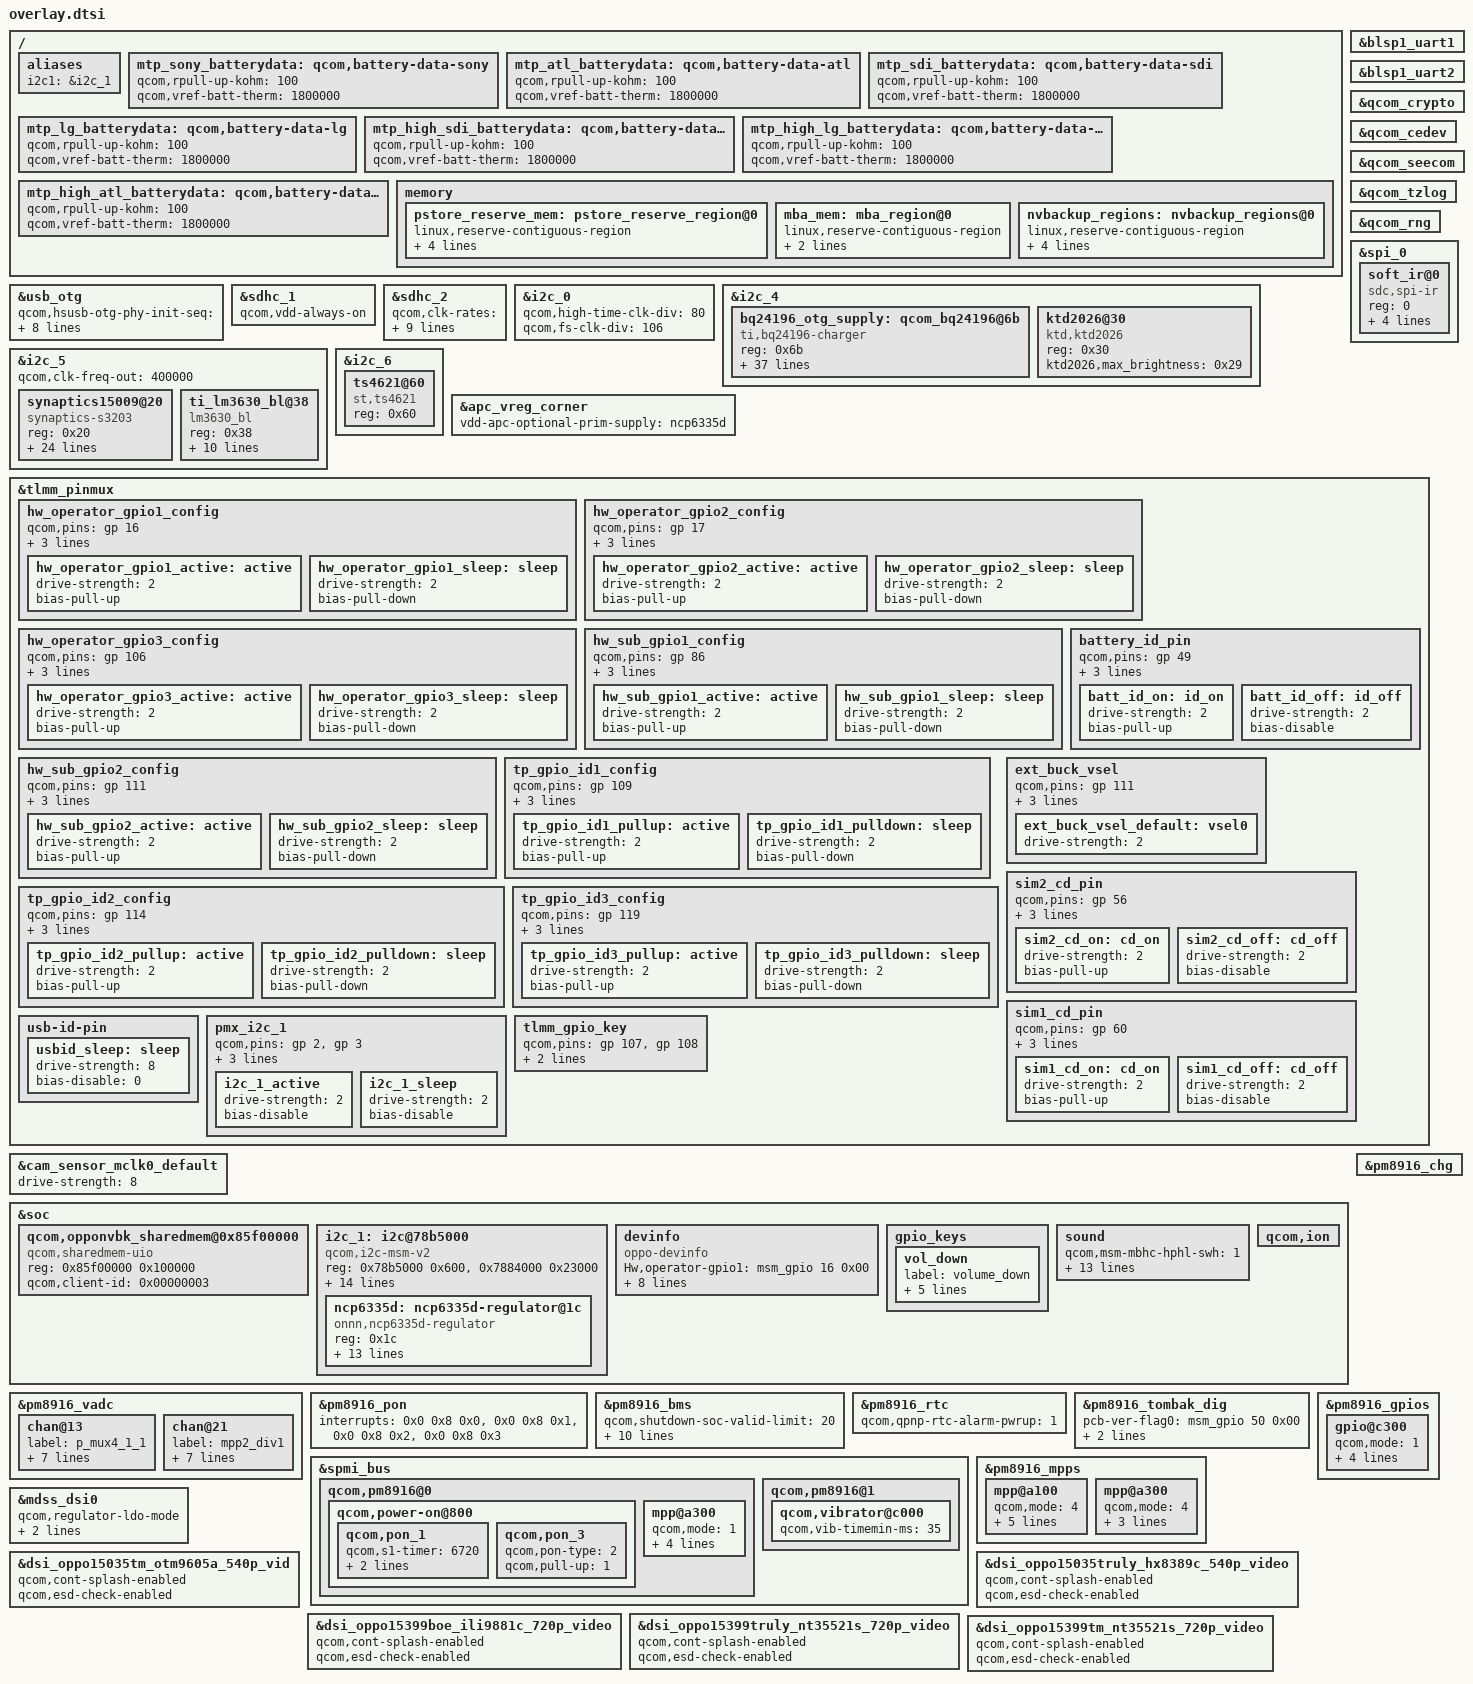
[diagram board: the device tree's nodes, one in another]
/* Copyright (c) 2021, The Linux Foundation. All rights reserved.
*  Copyright (c) 2021, Jebaitedneko.
*
* This program is free software; you can redistribute it and/or modify
* it under the terms of the GNU General Public License version 2 and
* only version 2 as published by the Free Software Foundation.
*
* This program is distributed in the hope that it will be useful,
* but WITHOUT ANY WARRANTY; without even the implied warranty of
* MERCHANTABILITY or FITNESS FOR A PARTICULAR PURPOSE.  See the
* GNU General Public License for more details.
*/

#include "msm8916-generic-sensors.dtsi"
#include "msm8916-camera-sensor-mtp.dtsi"

/ {
	aliases { i2c1 = &i2c_1; };

	mtp_sony_batterydata: qcom,battery-data-sony {
		qcom,rpull-up-kohm = <100>;
		qcom,vref-batt-therm = <1800000>;
		#include "batteries/batterydata-oppo-sony-4v35-2420mah.dtsi"
	};
	mtp_atl_batterydata: qcom,battery-data-atl {
		qcom,rpull-up-kohm = <100>;
		qcom,vref-batt-therm = <1800000>;
		#include "batteries/batterydata-oppo-atl-4v35-2420mah.dtsi"
	};
	mtp_sdi_batterydata: qcom,battery-data-sdi {
		qcom,rpull-up-kohm = <100>;
		qcom,vref-batt-therm = <1800000>;
		#include "batteries/batterydata-oppo-sdi-4v35-2420mah.dtsi"
	};
	mtp_lg_batterydata: qcom,battery-data-lg {
		qcom,rpull-up-kohm = <100>;
		qcom,vref-batt-therm = <1800000>;
		#include "batteries/batterydata-oppo-lg-4v35-2420mah.dtsi"
	};
	mtp_high_sdi_batterydata: qcom,battery-data-high-sdi {
		qcom,rpull-up-kohm = <100>;
		qcom,vref-batt-therm = <1800000>;
		#include "batteries/batterydata-oppo-sdi-4v4-2550mah.dtsi"
	};
	mtp_high_lg_batterydata: qcom,battery-data-high-lg {
		qcom,rpull-up-kohm = <100>;
		qcom,vref-batt-therm = <1800000>;
		#include "batteries/batterydata-oppo-lg-4v4-2550mah.dtsi"
	};
	mtp_high_atl_batterydata: qcom,battery-data-high-atl {
		qcom,rpull-up-kohm = <100>;
		qcom,vref-batt-therm = <1800000>;
		#include "batteries/batterydata-oppo-atl-4v4-2550mah.dtsi"
	};
	/delete-node/ qcom,battery-data;
	memory {
		pstore_reserve_mem: pstore_reserve_region@0 {
				linux,reserve-contiguous-region;
				linux,reserve-region;
				linux,remove-completely;
				reg = <0x0 0x9ff00000 0x0 0x400000>;
				label = "pstore_reserve_mem";
		};
		mba_mem: mba_region@0 {
			linux,reserve-contiguous-region;
			reg = <0 0 0 0x0200000>;
			label = "mba_mem";
		};
		/delete-node/ secure_region@0;
		nvbackup_regions: nvbackup_regions@0 {
			linux,reserve-contiguous-region;
			linux,reserve-region;
			linux,remove-completely;
			reg = <0 0x85f00000 0 0x100000>;
			label = "memory_nvbackup";
		};
	};
};
&blsp1_uart1 {
	status="ok";
};
&blsp1_uart2 {
	status="ok";
};
&qcom_crypto {
	status="ok";
};
&qcom_cedev {
	status="ok";
};
&qcom_seecom {
	status="ok";
};
&qcom_tzlog {
	status="ok";
};
&qcom_rng {
	status="ok";
};

&usb_otg {
	qcom,hsusb-otg-phy-init-seq = <0x74 0x80 0x66 0x81 0x24 0x82 0x13 0x83 0xffffffff>;
	qcom,hsusb-otg-mode = <3>;
	qcom,usbid-gpio = <&msm_gpio 110 0>;
	pinctrl-names = "default" , "active", "sleep";
	pinctrl-0 = <&usbid_default>;
	pinctrl-1 = <&usbid_default>;
	pinctrl-2 = <&usbid_sleep>;
	vbus_otg-supply = <&bq24196_otg_supply>;
	qcom,usbin-vadc = <&pm8916_vadc>;
};
&sdhc_1 {
	status="ok";
	qcom,vdd-always-on;
};
&sdhc_2 {
	status="ok";
	qcom,clk-rates = <400000 25000000 50000000 100000000>;
	vdd-gpio-en = <&msm_gpio 116 0x1>;
	/delete-property/ vdd-supply;
	interrupts = <0x0 0x01 0x02>;
	interrupt-names = "hc_irq", "pwr_irq", "status_irq";
	pinctrl-names = "default", "active", "sleep";
	pinctrl-0 = <&sdc2_cd_on &sim1_cd_on &sim2_cd_on>;
	pinctrl-1 = <&sdc2_clk_on &sdc2_cmd_on &sdc2_data_on &sdc2_cd_on>;
	pinctrl-2 = <&sdc2_clk_off &sdc2_cmd_off &sdc2_data_off &sdc2_cd_off>;
	cd-gpios = <&msm_gpio 38 0x0>;
};
&spi_0 {
	soft_ir@0{	
		compatible = "sdc,spi-ir";
		reg = <0>;
		spi-max-frequency = <50000000>;	
		hw-ver-gpio-h = <&msm_gpio 52 0x2008>;
		hw-ver-gpio-m = <&msm_gpio 51 0x2008>;	
		hw-ver-gpio-l = <&msm_gpio 50 0x2008>;
	};
};
&i2c_0 {
	qcom,high-time-clk-div = <80>;
	qcom,fs-clk-div = <106>;
};
&i2c_4 {
	bq24196_otg_supply:	qcom_bq24196@6b {
		compatible = "ti,bq24196-charger";
		reg = <0x6b>;
		vcc_i2c_opcharger-supply = <&pm8916_l5>;
		
		qcom,irq-gpio = <&msm_gpio 62 0x00>;
		//qcom,usbin-switch-gpio = <&pm8916_gpios 3 0>;

		
		qcom,disable-apsd;
		qcom,using-pmic-therm;
		//qcom,bms-controlled-charging;
		qcom,charger-inhibit-disabled;
		qcom,bms-psy-name = "bms";
		qcom,chg-vadc = <&pm8916_vadc>;
		qcom,chg-adc_tm = <&pm8916_adc_tm>;

		qcom,iterm-ma = <130>;									/*Charge termination current*/
		qcom,recharge-mv = <200>;							
		qcom,fast-charger-project-sign= <0>;					
		qcom,fastchg-current-max-ma = <1500>;					
		qcom,input-current-max-ma = <1500>;				
		qcom,float-voltage-mv = <4370>;

		qcom,hot_bat_decidegc = <530>;							/* hot battery temperature in decidegC = 53*/
		qcom,temp_hot_vfloat_mv = <4110>;							/* hot battery temperature cutoff voltage =4.1V (45~55)*/
		qcom,temp_hot_fastchg_current_ma = <520>;					/* hot battery temperature fast current   =0.75A (45~55)*/

		qcom,warm_bat_decidegc = <450>;							/* Warm battery temperature in decidegC= 43*/
		qcom,temp_warm_vfloat_mv = <4370>;						/* warn battery temperature cutoff voltage =4.1V (5~45)*/
		qcom,temp_warm_fastchg_current_ma = <1500>;				/* warn battery temperature fast current   =0.75A (5~45)*/

		qcom,pre_normal_bat_decidegc = <220>;						/* pre_cool battery temperature in decidegC= 22*/	
		qcom,temp_pre_normal_vfloat_mv = <4370>;						/* warn battery temperature cutoff voltage =4.1V (5~45)*/
		qcom,temp_pre_normal_fastchg_current_ma = <1050>;			/* warn battery temperature fast current   =0.75A (5~45)*/

		qcom,pre_cool_bat_decidegc = <120>;						/* pre_cool battery temperature in decidegC= 12*/	
		qcom,temp_pre_cool_vfloat_mv = <4370>;					/* pre_cool battery temperature cutoff voltage =4.2V (0~5)*/
		qcom,temp_pre_cool_fastchg_current_ma = <535>;			/* pre_cool battery temperature fast current   =0.75A (0~5)*/

		qcom,pre_cool1_bat_decidegc = <50>;						/* pre_cool battery temperature in decidegC= 12*/	
		qcom,temp_pre_cool1_vfloat_mv = <4370>;					/* pre_cool battery temperature cutoff voltage =4.2V (0~5)*/
		qcom,temp_pre_cool1_fastchg_current_ma = <350>;			/* pre_cool battery temperature fast current   =0.75A (0~5)*/

		qcom,cool_bat_decidegc = <0>;								/* cool battery temperature in decidegC= 0*/
		qcom,temp_cool_vfloat_mv = <4000>;						/* cool battery temperature cutoff voltage =4.0V (-10~0) */
		qcom,temp_cool_fastchg_current_ma = <256>;				/* cool battery temperature fast current   =0.25A(-10~0)*/

		qcom,cold_bat_decidegc = <30>;							/* cold battery temperature in decidegC= -3*/
		qcom,bat_present_decidegc = <200>;						/* battery decidegc temperature in decidegC= -20*/
		qcom,non_standard_vfloat_mv = <4000>;
		qcom,non_standard_fastchg_current_ma = <512>;

		//qcom,batt-id-gpio = <&msm_gpio 49 0x00>;
		//pinctrl-names = "default";
		//pinctrl-0 = <&batt_id_on>;

		regulator-name = "bq24196_otg_vreg";
	};
	ktd2026@30 {
		status = "okay";
		compatible = "ktd,ktd2026";
		reg = <0x30>;
		//ktd2026,max_brightness = <0x07>;  //current:  0x00:0.125ma 0x07 1ma  0x29:5.25ma  0x4f:10ma  0xbf-0xff:24ma
		ktd2026,max_brightness = <0x29>;  //current:  0x00:0.125ma 0x07 1ma  0x29:5.25ma  0x4f:10ma  0xbf-0xff:24ma
					//ktd2026,max_brightness = <0x4F>;  //current:  0x00:0.125ma   0x4f:10ma  0xbf-0xff:24ma
					//ktd2026,max_brightness = <0xff>;  //current:  0x00:0.125ma 0x07 1ma  0x29:5.25ma  0x4f:10ma  0xbf-0xff:24ma
	};
};
&i2c_5 {
	qcom,clk-freq-out = <400000>;
	/delete-node/ synaptics@20;
	synaptics15009@20 {/*tong.han add for TP */
		compatible = "synaptics-s3203";
		reg = <0x20>;
		interrupt-parent = <&msm_gpio>;
		interrupts = <13 0x2008>;
		synaptics,irq-gpio = <&msm_gpio 13 0x2008>;
		synaptics,id1-gpio = <&msm_gpio 109 0x00>;
		synaptics,id2-gpio = <&msm_gpio 114 0x00>;
		synaptics,id3-gpio = <&msm_gpio 119 0x00>;
		//synaptics,reset-gpio = <&pm8916_gpios 2 0x00>;
		
		pinctrl-names = "default","tp_id_pull_up","tp_id_pull_down";
		pinctrl-0 = <&ts_int_active   &tp_gpio_id1_pullup   &tp_gpio_id2_pullup   &tp_gpio_id3_pullup>;
		pinctrl-1 = <&tp_gpio_id1_pullup   &tp_gpio_id2_pullup   &tp_gpio_id3_pullup>;
		pinctrl-2 = <&tp_gpio_id1_pulldown &tp_gpio_id2_pulldown &tp_gpio_id3_pulldown>;			
		
		synaptics,max-num-support = <10>;
		synaptics,max-x-point = <10>;
		synaptics,button-map= <100 140 1400>;//width-height-y.position
		synaptics,tx-rx-num = <13 23>;
		synaptics,display-coords = <720 1280>;
		synaptics,panel-coords = <1100 1745>;//max_x,max_y of display area--Not include virtual keys!
		vdd_2v8-supply = <&pm8916_l17>;
		vcc_i2c_1v8-supply = <&pm8916_l6>;
		synaptics,black-gesture-enabled;
		//synaptics,glove-mode-enabled;
		synaptics,i2c-pull-up;
		synaptics,power-down;
		synaptics,disable-gpios;
	};
	ti_lm3630_bl@38 {
		compatible = "lm3630_bl";
		reg = <0x38>;
		ti,bank-a-ctrl = <0x05>;
		ti,init-brt-led1 = <200>;
		ti,init-brt-led2 = <200>;
		ti,max-brt-led1 = <255>;
		ti,max-brt-led2 = <255>;
		ti,pwm-active = <0>;
		ti,pwm-ctrl = <0>;
		ti,pwm-period = <255>;
		bl_i2c_1v8-supply = <&pm8916_l6>;
		ti,bl-enable-gpio = <&msm_gpio 69 0x00>;
	};
};
&i2c_6 {
	ts4621@60 {
				status = "okay";
				compatible = "st,ts4621";
				reg = <0x60>;
	};
};
&apc_vreg_corner {
	vdd-apc-optional-prim-supply = <&ncp6335d>;
};
&tlmm_pinmux {
	hw_operator_gpio1_config {
		/* MCLK */
		qcom,pins = <&gp 16>;
		qcom,num-grp-pins = <1>;
		qcom,pin-func = <0>;
		label = "hw_operator_gpio1_config";
		/* active state */
		hw_operator_gpio1_active: active {
			drive-strength = <2>; /* 2 mA */
			bias-pull-up; /*  PULL  UP*/
		};
		hw_operator_gpio1_sleep: sleep {
			drive-strength = <2>; /* 2 mA */
			bias-pull-down; /* PULL DOWN */
		};			
	};
	hw_operator_gpio2_config {
		/* MCLK */
		qcom,pins = <&gp 17>;
		qcom,num-grp-pins = <1>;
		qcom,pin-func = <0>;
		label = "hw_operator_gpio2_config";
		/* active state */
		hw_operator_gpio2_active: active {
			drive-strength = <2>; /* 2 mA */
			bias-pull-up; /*  PULL  UP*/
		};
		hw_operator_gpio2_sleep: sleep {
			drive-strength = <2>; /* 2 mA */
			bias-pull-down; /* PULL DOWN */
		};			
	};
	hw_operator_gpio3_config {
		/* MCLK */
		qcom,pins = <&gp 106>;
		qcom,num-grp-pins = <1>;
		qcom,pin-func = <0>;
		label = "hw_operator_gpio3_config";
		/* active state */
		hw_operator_gpio3_active: active {
			drive-strength = <2>; /* 2 mA */
			bias-pull-up; /*  PULL  UP*/
		};
		hw_operator_gpio3_sleep: sleep {
			drive-strength = <2>; /* 2 mA */
			bias-pull-down; /* PULL DOWN */
		};			
	};
	hw_sub_gpio1_config {
		/* MCLK */
		qcom,pins = <&gp 86>;
		qcom,num-grp-pins = <1>;
		qcom,pin-func = <0>;
		label = "hw_sub_gpio1_config";
		/* active state */
		hw_sub_gpio1_active: active {
			drive-strength = <2>; /* 2 mA */
			bias-pull-up; /*  PULL  UP*/
		};
		hw_sub_gpio1_sleep: sleep {
			drive-strength = <2>; /* 2 mA */
			bias-pull-down; /* PULL DOWN */
		};			
	};
	hw_sub_gpio2_config {
		/* MCLK */
		qcom,pins = <&gp 111>;
		qcom,num-grp-pins = <1>;
		qcom,pin-func = <0>;
		label = "hw_sub_gpio2_config";
		/* active state */
		hw_sub_gpio2_active: active {
			drive-strength = <2>; /* 2 mA */
			bias-pull-up; /*  PULL  UP*/
		};
		hw_sub_gpio2_sleep: sleep {
			drive-strength = <2>; /* 2 mA */
			bias-pull-down; /* PULL DOWN */
		};			
	};
	tp_gpio_id1_config {
		/* MCLK */
		qcom,pins = <&gp 109>;
		qcom,num-grp-pins = <1>;
		qcom,pin-func = <0>;
		label = "tp_gpio_id1_config";
		/* active state */
		tp_gpio_id1_pullup: active {
			drive-strength = <2>; /* 2 mA */
			bias-pull-up; /*  PULL  UP*/
		};
		tp_gpio_id1_pulldown: sleep {
			drive-strength = <2>; /* 2 mA */
			bias-pull-down; /* PULL DOWN */
		};			
	};
	tp_gpio_id2_config {
		/* MCLK */
		qcom,pins = <&gp 114>;
		qcom,num-grp-pins = <1>;
		qcom,pin-func = <0>;
		label = "tp_gpio_id2_config";
		/* active state */
		tp_gpio_id2_pullup: active {
			drive-strength = <2>; /* 2 mA */
			bias-pull-up; /*  PULL  UP*/
		};
		tp_gpio_id2_pulldown: sleep {
			drive-strength = <2>; /* 2 mA */
			bias-pull-down; /* PULL DOWN */
		};			
	};
	tp_gpio_id3_config {
		/* MCLK */
		qcom,pins = <&gp 119>;
		qcom,num-grp-pins = <1>;
		qcom,pin-func = <0>;
		label = "tp_gpio_id3_config";
		/* active state */
		tp_gpio_id3_pullup: active {
			drive-strength = <2>; /* 2 mA */
			bias-pull-up; /*  PULL  UP*/
		};
		tp_gpio_id3_pulldown: sleep {
			drive-strength = <2>; /* 2 mA */
			bias-pull-down; /* PULL DOWN */
		};			
	};
	battery_id_pin {
		qcom,pins = <&gp 49>;
		qcom,num-grp-pins = <1>;
		qcom,pin-func = <0>;
		label = "battery-id-gpio";
		batt_id_on: id_on {
			drive-strength = <2>;
			bias-pull-up;
		};
		batt_id_off: id_off {
			drive-strength = <2>;
			bias-disable;
		};
	};
	ext_buck_vsel {
		qcom,pins = <&gp 111>;
		qcom,num-grp-pins = <1>;
		qcom,pin-func = <0>;
		label = "ext-buck-vsel";

		ext_buck_vsel_default: vsel0 {
			drive-strength = <2>;
		};
	};
	sim2_cd_pin {
		qcom,pins = <&gp 56>;
		qcom,num-grp-pins = <1>;
		qcom,pin-func = <0>;
		label = "sim2-cd-gpio";
		sim2_cd_on: cd_on {
			drive-strength = <2>;
			bias-pull-up;
			};
		sim2_cd_off: cd_off {
			drive-strength = <2>;
			bias-disable;
			};
	};
	sim1_cd_pin {
		qcom,pins = <&gp 60>;
		qcom,num-grp-pins = <1>;
		qcom,pin-func = <0>;
		label = "sim1-cd-gpio";
		sim1_cd_on: cd_on {
			drive-strength = <2>;
			bias-pull-up;
			};
		sim1_cd_off: cd_off {
			drive-strength = <2>;
			bias-disable;
			};
	};
	usb-id-pin {
		usbid_sleep: sleep {
			drive-strength = <8>;
			bias-disable = <0>;
		};
	};
	pmx_i2c_1 {
		qcom,pins = <&gp 2>, <&gp 3>; /* SDA, SCL */
		qcom,num-grp-pins = <2>;
		qcom,pin-func = <3>;
		label = "pmx_i2c_1";

		i2c_1_active: i2c_1_active {
			drive-strength = <2>;
			bias-disable;
		};

		i2c_1_sleep: i2c_1_sleep {
			drive-strength = <2>;
			bias-disable;
		};
	};
	tlmm_gpio_key {
		qcom,pins = <&gp 107>, <&gp 108>;
		qcom,pin-func = <0>;
		qcom,num-grp-pins = <2>;
	};
};
&cam_sensor_mclk0_default { drive-strength = <8>; };

&soc {
	qcom,opponvbk_sharedmem@0x85f00000 {
		compatible = "qcom,sharedmem-uio";
		reg = <0x85f00000 0x100000>;
		reg-names = "opponvbk";
		qcom,client-id = <0x00000003>;
	};

	i2c_1: i2c@78b5000 { /* BLSP1 QUP1 */
		compatible = "qcom,i2c-msm-v2";
		#address-cells = <1>;
		#size-cells = <0>;
		reg-names = "qup_phys_addr", "bam_phys_addr";
		reg = <0x78b5000 0x600>,
		      <0x7884000 0x23000>;
		interrupt-names = "qup_irq", "bam_irq";
		interrupts = <0 95 0>, <0 238 0>;
		clocks = <&clock_gcc clk_gcc_blsp1_ahb_clk>,
			 <&clock_gcc clk_gcc_blsp1_qup1_i2c_apps_clk>;
		clock-names = "iface_clk", "core_clk";
		qcom,clk-freq-out = <100000>;
		qcom,clk-freq-in  = <19200000>;
		pinctrl-names = "i2c_active", "i2c_sleep";
		pinctrl-0 = <&i2c_1_active>;
		pinctrl-1 = <&i2c_1_sleep>;
		qcom,noise-rjct-scl = <0>;
		qcom,noise-rjct-sda = <0>;
		qcom,bam-pipe-idx-cons = <4>;
		qcom,bam-pipe-idx-prod = <5>;
		qcom,high-time-clk-div = <80>;//sjc add
		qcom,fs-clk-div = <106>;
		qcom,master-id = <86>;

		ncp6335d: ncp6335d-regulator@1c {
			compatible = "onnn,ncp6335d-regulator";
			reg = <0x1c>;
			onnn,vsel = <0>;
			onnn,slew-ns = <3333>;
			onnn,step-size = <6250>;
			onnn,min-slew-ns = <416>;
			onnn,max-slew-ns = <3333>;
			regulator-min-microvolt = <1050000>;
			regulator-max-microvolt = <1350000>;
			onnn,min-setpoint = <600000>;
			pintrl-names = "default";
			pinctrl-0 = <&ext_buck_vsel_default>;
			onnn,vsel-gpio = <&msm_gpio 111 1>;
			onnn,discharge-enable;
			onnn,restore-reg;
		};
	};
	devinfo {
			compatible = "oppo-devinfo";
			Hw,operator-gpio1 = <&msm_gpio 16 0x00>;
			Hw,operator-gpio2 = <&msm_gpio 17 0x00>;
			Hw,operator-gpio3 = <&msm_gpio 106 0x00>;
			Hw,sub_hwid_1 = <&msm_gpio 86 0x00>;
			Hw,sub_hwid_2= <&msm_gpio 111 0x00>;
			pinctrl-names = "default";
			pinctrl-0 = <&hw_operator_gpio1_active &hw_operator_gpio2_active &hw_operator_gpio3_active &hw_sub_gpio1_active &hw_sub_gpio2_active>;
	};
	gpio_keys {
		vol_down {
			label = "volume_down";
			gpios = <&msm_gpio 108 0x1>;
			linux,input-type = <1>;
			linux,code = <114>;
			gpio-key,wakeup;
			debounce-interval = <15>;
		};
	};
	sound {
		qcom,msm-mbhc-hphl-swh = <1>;
		qcom,msm-micbias2-ext-cap;
		qcom,audio-routing-15009-after-evt2 =
			"RX_BIAS", "MCLK",
			"SPK_RX_BIAS", "MCLK",
			"INT_LDO_H", "MCLK",
			"MIC BIAS External", "Handset Mic",
			"MIC BIAS External2", "Headset Mic",
			"MIC BIAS External", "Secondary Mic",
			"AMIC1", "MIC BIAS External",
			"AMIC2", "MIC BIAS External2",
			"AMIC3", "MIC BIAS External";
		spk-pa-en = <&msm_gpio 120 0x00>;
		yda145_boost-en = <&msm_gpio 118 0x00>;
		/delete-property/ qcom,cdc-us-euro-gpios;
		pcb-ver-flag0 = <&msm_gpio 50 0x00>;
		pcb-ver-flag1 = <&msm_gpio 51 0x00>;
		pcb-ver-flag2 = <&msm_gpio 52 0x00>;
	};
	qcom,ion {
		/delete-node/ qcom,ion-heap@8;
	};
};

&pm8916_vadc {
	chan@13 {
			label = "p_mux4_1_1";
			reg = <0x13>;
			qcom,decimation = <0>;
			qcom,pre-div-channel-scaling = <0>;
			qcom,calibration-type = "absolute";
			qcom,scale-function = <0>;
			qcom,hw-settle-time = <2>;
			qcom,fast-avg-setup = <0>;
			};
	chan@21 {
		label = "mpp2_div1";
		reg = <0x21>;		//channel for MPP2(P_MUX2_3_1)
		qcom,decimation = <0>;
		qcom,pre-div-channel-scaling = <1>;	//1:3 scale
		qcom,calibration-type = "ratiometric";
		qcom,scale-function = <0>;
		qcom,hw-settle-time = <2>;
		qcom,fast-avg-setup = <0>;
	};
};

&pm8916_pon{
	interrupts = <0x0 0x8 0x0>,
	<0x0 0x8 0x1>,
	<0x0 0x8 0x2>,
	<0x0 0x8 0x3>;
	interrupt-names = "kpdpwr", "resin", "cblpwr","kpdpwr-bark";
};
&pm8916_chg {
	status="ok";
};
&pm8916_bms {
	status="ok";
};
&pm8916_rtc {
	qcom,qpnp-rtc-alarm-pwrup = <1>;
};
&pm8916_bms {
	qcom,shutdown-soc-valid-limit = <20>;
};
&pm8916_tombak_dig {
	pcb-ver-flag0 = <&msm_gpio 50 0x00>;
	pcb-ver-flag1 = <&msm_gpio 51 0x00>;
	pcb-ver-flag2 = <&msm_gpio 52 0x00>;
};
&spmi_bus {
	qcom,pm8916@0 {
		qcom,power-on@800 {
			qcom,pon_1 {
				qcom,s1-timer = <6720>;
				qcom,s2-type = <7>;
				qcom,use-bark;
			};
			qcom,pon_3{
				qcom,pon-type = <2>;
				qcom,pull-up = <1>;
			};
		};
		mpp@a300 {
			qcom,mode = <1>; /* Digital Output*/
			qcom,invert = <0>; /* QPNP_PIN_INVERT_DISABLE */
			qcom,vin-sel = <2>; /* QPNP_PIN_VIN2 = S3 = 1.8V */
			qcom,src-sel = <0>; /* Function constant */
			qcom,master-en = <1>; /* Enable MPP */
		};
		/delete-node/ qcom,leds@a100;
	};
	qcom,pm8916@1 {
		qcom,vibrator@c000 {
			status="ok";
			qcom,vib-timemin-ms = <35>;
		};
	};
};

&pm8916_mpps {
	mpp@a100 { /* MPP 2 */
		/*Fuchun.Liao@Mobile.BSP.CHG 2015-07-14 modify for set MPP2 to iadc*/
		status = "ok";
		qcom,mode = <4>;		/* QPNP_PIN_MODE_AIN */
		qcom,invert = <0>;		/* Disable invert */
		qcom,output-type = <0>;	/* CMOS */
		qcom,src-sel = <0>;		/* MPP Constant */
		qcom,ain-route = <1>;	/* QPNP_PIN_AIN_AMUX_CH6 = 1 for MPP2 */
		qcom,master-en = <1>;		/* Enable MPP */
	};
	mpp@a300 { /* MPP 4 */
		/* OPPO 2016-1-15 sjc modify for PM8916 MPP4 to adc */
		qcom,mode = <4>; // QPNP_PIN_MODE_AIN 
		qcom,src-sel = <0>; // QPNP_PIN_SEL_FUNC_CONSTANT 
		qcom,ain-route = <3>; // QPNP_PIN_AIN_AMUX_CH8 
		qcom,master-en = <1>; // Enable features 
	};
};

&pm8916_gpios {
	gpio@c300 { /* GPIO 4 */
		/* External regulator control for APC */
		/*Fuchun.Liao@Mobile.BSP.CHG 2014-08-06 modify pm_gpio_4 output VPH_PWR for DVT PCBA*/
		status = "ok";
		qcom,mode = <1>; /* QPNP_PIN_MODE_DIG_OUT */
		qcom,vin-sel = <0>; /* VPH_PWR */
		qcom,src-sel = <0>; /* QPNP_PIN_SEL_FUNC_CONSTANT */
		qcom,out-strength = <2>; /* QPNP_PIN_OUT_STRENGTH_MED */
		qcom,master-en = <1>;
		/*Fuchun.Liao modify end*/
	};
};

&pm8916_bms {
	qcom,battery-data-sony = <&mtp_sony_batterydata>;
	qcom,battery-data-atl = <&mtp_atl_batterydata>;
	qcom,battery-data-sdi = <&mtp_sdi_batterydata>;
	qcom,battery-data-lg = <&mtp_lg_batterydata>;
/*Mofei@Mobile.BSP.CHG 2016-1-18 modify for batterydata*/
	qcom,battery-data-high-atl = <&mtp_high_atl_batterydata>;
	qcom,battery-data-high-sdi = <&mtp_high_sdi_batterydata>;
	qcom,battery-data-high-lg = <&mtp_high_lg_batterydata>;
	/delete-property/ qcom,battery-data;
};

#include "panels/dsi-panel-oppo15035tm-otm9605a-540p-video.dtsi"
#include "panels/dsi-panel-oppo15035truly-hx8389c-540p-video.dtsi"
#include "panels/dsi-panel-oppo15399boe-ili9881c-720p-video.dtsi"
#include "panels/dsi-panel-oppo15399truly-nt35521s-720p-video.dtsi"
#include "panels/dsi-panel-oppo15399tm-nt35521s-720p-video.dtsi"

&mdss_dsi0 {
	qcom,regulator-ldo-mode;
	qcom,dsi-pref-prim-pan = <&dsi_oppo15035tm_otm9605a_540p_vid>;
};

&dsi_oppo15035tm_otm9605a_540p_vid {
      qcom,cont-splash-enabled;
      qcom,esd-check-enabled;
};
&dsi_oppo15035truly_hx8389c_540p_video {
      qcom,cont-splash-enabled;
      qcom,esd-check-enabled;
};
&dsi_oppo15399boe_ili9881c_720p_video {
      qcom,cont-splash-enabled;
      qcom,esd-check-enabled;
};
&dsi_oppo15399truly_nt35521s_720p_video{
      qcom,cont-splash-enabled;
      qcom,esd-check-enabled;  
};
&dsi_oppo15399tm_nt35521s_720p_video{
      qcom,cont-splash-enabled;
      qcom,esd-check-enabled;  
};
